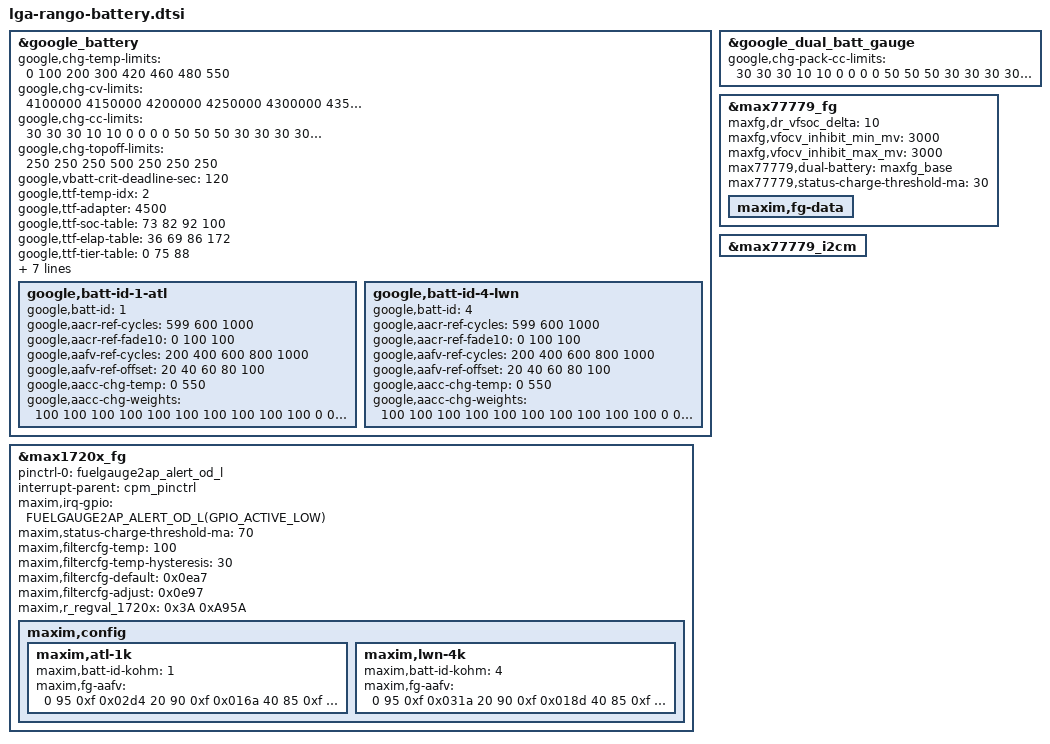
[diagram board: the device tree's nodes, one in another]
// SPDX-License-Identifier: GPL-2.0-only
/*
 * Battery device tree entries specific to Rango
 *
 * Copyright 2024 Google LLC
 *
 */

#include "google-base/platform/lga-platform-battery.dtsi"
#include "google-base/platform/lga-dual-battery-common.dtsi"

&google_battery {
	google,chg-temp-limits = <0 100 200 300 420 460 480 550>;
	google,chg-cv-limits = <
		4100000 4150000 4200000 4250000 4300000 4350000 4370000 4480000 4500000>;
	google,chg-cc-limits = <
		 30  30  30  10  10   0   0   0   0
		 50  50  50  30  30  30  30  30  30
		110 110 105 105 105 105 105  50  50
		110 110 105 105 105 105 105  50  50
		 90  90  90  90  90  90  50  50   0
		 50  50  50  50   0   0   0   0   0
		 30   0   0   0   0   0   0   0   0
	>;

	google,chg-topoff-limits = <250 250 250 500 250 250 250>;

	google,vbatt-crit-deadline-sec = <120>;

	google,ttf-temp-idx= <2>;
	google,ttf-adapter = <4500>;
	google,ttf-soc-table =  <73 82 92 100>;
	google,ttf-elap-table = <36 69 86 172>;
	google,ttf-tier-table = <0 75 88>;

	google,aacr-config = <1>; /* enabled, no opt out */
	google,aafv-config = <1>; /* enabled, no opt out */

	/* 90% after 600 cycles, 80% after 1000 cycles */
	google,aacr-algo = <3>;
	google,aacr-cliff-capacity-rate = <80>;
	google,aacr-cycle-max = <1000>;

	google,bpst-enable;
	google,bpst-dual-batt;

	google,batt-id-1-atl {
		google,batt-id = <1>;
		google,aacr-ref-cycles = <599 600 1000>;
		google,aacr-ref-fade10 = <  0 100  100>;
		google,aafv-ref-cycles = <200 400 600 800 1000>;
		google,aafv-ref-offset = < 20  40  60  80  100>;
		google,aacc-chg-temp = <0 550>;
		google,aacc-chg-weights = < /* units: 1/1000 cycles */
			100 100 100 100 100 100 100 100 100 100 /* soc:  1 ~  10, temp_idx: 0 */
			  0   0   0   0   0   0   0   0   0   0 /* soc: 11 ~  20, temp_idx: 0 */
			  0   0   0   0   0   0   0   0   0   0 /* soc: 21 ~  30, temp_idx: 0 */
			  0   0   0   0   0   0   0   0   0   0 /* soc: 31 ~  40, temp_idx: 0 */
			  0   0   0   0   0   0   0   0   0   0 /* soc: 41 ~  50, temp_idx: 0 */
			  0   0   0   0   0   0   0   0   0   0 /* soc: 51 ~  60, temp_idx: 0 */
			  0   0   0   0   0   0   0   0   0   0 /* soc: 61 ~  70, temp_idx: 0 */
			  0   0   0   0   0   0   0   0   0   0 /* soc: 71 ~  80, temp_idx: 0 */
			  0   0   0   0   0   0   0   0   0   0 /* soc: 81 ~  90, temp_idx: 0 */
			  0   0   0   0   0   0   0   0   0   0 /* soc: 91 ~ 100, temp_idx: 0 */
		>;
	};
	google,batt-id-4-lwn {
		google,batt-id = <4>;
		google,aacr-ref-cycles = <599 600 1000>;
		google,aacr-ref-fade10 = <  0 100  100>;
		google,aafv-ref-cycles = <200 400 600 800 1000>;
		google,aafv-ref-offset = < 20  40  60  80  100>;
		google,aacc-chg-temp = <0 550>;
		google,aacc-chg-weights = < /* units: 1/1000 cycles */
			100 100 100 100 100 100 100 100 100 100 /* soc:  1 ~  10, temp_idx: 0 */
			  0   0   0   0   0   0   0   0   0   0 /* soc: 11 ~  20, temp_idx: 0 */
			  0   0   0   0   0   0   0   0   0   0 /* soc: 21 ~  30, temp_idx: 0 */
			  0   0   0   0   0   0   0   0   0   0 /* soc: 31 ~  40, temp_idx: 0 */
			  0   0   0   0   0   0   0   0   0   0 /* soc: 41 ~  50, temp_idx: 0 */
			  0   0   0   0   0   0   0   0   0   0 /* soc: 51 ~  60, temp_idx: 0 */
			  0   0   0   0   0   0   0   0   0   0 /* soc: 61 ~  70, temp_idx: 0 */
			  0   0   0   0   0   0   0   0   0   0 /* soc: 71 ~  80, temp_idx: 0 */
			  0   0   0   0   0   0   0   0   0   0 /* soc: 81 ~  90, temp_idx: 0 */
			  0   0   0   0   0   0   0   0   0   0 /* soc: 91 ~ 100, temp_idx: 0 */
		>;
	};
};

&google_dual_batt_gauge {
	google,chg-pack-cc-limits = <
		 30  30  30  10  10   0   0   0   0
		 50  50  50  30  30  30  30  30  30
		115 115 110 110 110 110 110  50  50
		115 115 110 110 110 110 110  50  50
		 90  90  90  90  90  90  50  50   0
		 50  50  50  50   0   0   0   0   0
		 30   0   0   0   0   0   0   0   0
	>;
};

&max77779_fg {
	maxfg,dr_vfsoc_delta = <10>;
	maxfg,vfocv_inhibit_min_mv = <3000>;
	maxfg,vfocv_inhibit_max_mv = <3000>;
	max77779,dual-battery = "maxfg_base";
	max77779,status-charge-threshold-ma = <30>;
	maxim,fg-data {
		#include "lga-rango-battery-data.dtsi"
	};
};

&max77779_i2cm {
	#include "google-base/platform/lga-max1720x-fg.dtsi"
};


&max1720x_fg {
	pinctrl-0 = <&fuelgauge2ap_alert_od_l>;

	interrupt-parent = <&cpm_pinctrl>;
	maxim,irq-gpio = <FUELGAUGE2AP_ALERT_OD_L(GPIO_ACTIVE_LOW)>;

	maxim,status-charge-threshold-ma = <70>;

	maxim,filtercfg-temp = <100>;
	maxim,filtercfg-temp-hysteresis = <30>;
	maxim,filtercfg-default = /bits/ 16 <0x0ea7>;
	maxim,filtercfg-adjust = /bits/ 16 <0x0e97>;
	maxim,r_regval_1720x =  /bits/ 16 <
		0x3A 0xA95A	/* VEmpty */
	>;

	maxim,config {
		maxim,atl-1k {
			maxim,batt-id-kohm = <1>;
			maxim,fg-aafv = /bits/ 32 <
				0    95  0xf  0x02d4
				20   90  0xf  0x016a
				40   85  0xf  0x016a
				60   80  0xf  0x016a
				80   75  0xf  0x016a
				100  70  0xf  0x016a
			>;
		};
		maxim,lwn-4k {
			maxim,batt-id-kohm = <4>;
			maxim,fg-aafv = /bits/ 32 <
				0    95  0xf  0x031a
				20   90  0xf  0x018d
				40   85  0xf  0x018d
				60   80  0xf  0x018d
				80   75  0xf  0x018d
				100  70  0xf  0x018d
			>;
		};
	};
};
